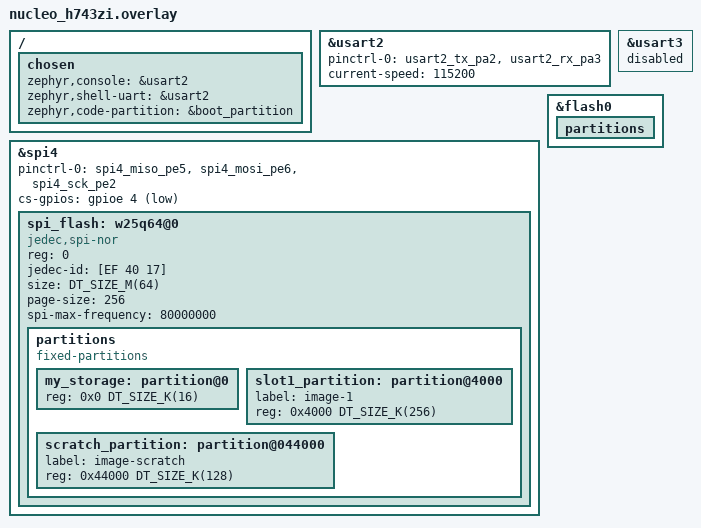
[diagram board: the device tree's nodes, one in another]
/ {
    chosen {
		zephyr,console = &usart2;
		zephyr,shell-uart = &usart2;
        zephyr,code-partition = &boot_partition;
    };
};

&usart2 {
    pinctrl-0 = <&usart2_tx_pa2 &usart2_rx_pa3>;
    pinctrl-names = "default";
    current-speed = <115200>;
    status = "okay";
};

&usart3 {
    status = "disabled";
};

&spi4 {
    pinctrl-0 = <&spi4_miso_pe5 &spi4_mosi_pe6 &spi4_sck_pe2>;
    pinctrl-names = "default";

    cs-gpios = <&gpioe 4 GPIO_ACTIVE_LOW>;
    status = "okay";

    spi_flash: w25q64@0 {
        compatible = "jedec,spi-nor";
        reg = <0>;

        jedec-id = [EF 40 17];
        size = <DT_SIZE_M(64)>;
        page-size = <256>;
        spi-max-frequency = <80000000>;
        status = "okay";
    };
};

&spi_flash {
    partitions {
        compatible = "fixed-partitions";
        #address-cells = <1>;
        #size-cells = <1>;

        my_storage: partition@0 {
            reg = <0x0 DT_SIZE_K(16)>;
        };

        slot1_partition: partition@4000 {
            label = "image-1";
            reg = <0x4000 DT_SIZE_K(256)>;
        };

        scratch_partition: partition@044000 {
            label = "image-scratch";
            reg = <0x44000 DT_SIZE_K(128)>;
        };
    };
};

&flash0 {
    partitions {
        /delete-node/ partition@80000;
        /delete-node/ partition@c0000;
    };
};
